CM_ "AUTOGENERATED FILE, DO NOT EDIT";

CM_ "hyundai_kia_mando_front_radar.dbc starts here";

VERSION ""

NS_ :

BS_:

BU_: XXX

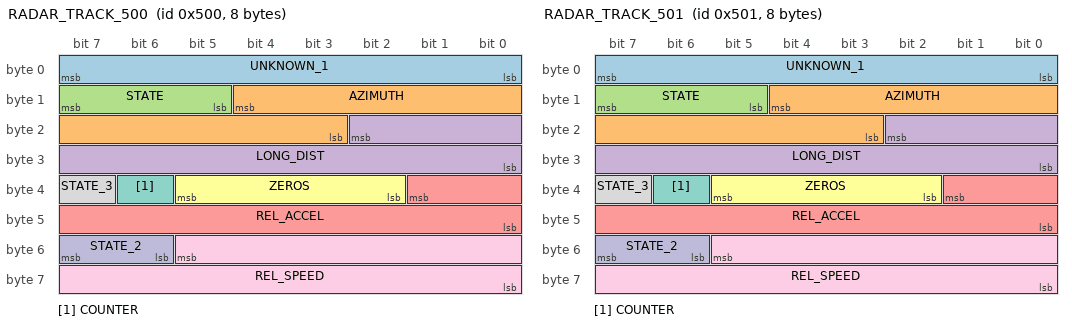
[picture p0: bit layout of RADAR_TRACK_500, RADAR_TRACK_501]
BO_ 1280 RADAR_TRACK_500: 8 RADAR
 SG_ UNKNOWN_1 : 7|8@0- (1,0) [-128|127] "" XXX
 SG_ AZIMUTH : 12|10@0- (0.2,0) [-102.4|102.2] "" XXX
 SG_ STATE : 15|3@0+ (1,0) [0|7] "" XXX
 SG_ LONG_DIST : 18|11@0+ (0.1,0) [0|204.7] "" XXX
 SG_ REL_ACCEL : 33|10@0- (0.02,0) [-10.24|10.22] "" XXX
 SG_ ZEROS : 37|4@0+ (1,0) [0|255] "" XXX
 SG_ COUNTER : 38|1@0+ (1,0) [0|1] "" XXX
 SG_ STATE_3 : 39|1@0+ (1,0) [0|1] "" XXX
 SG_ REL_SPEED : 53|14@0- (0.01,0) [-81.92|81.92] "" XXX
 SG_ STATE_2 : 55|2@0+ (1,0) [0|3] "" XXX

BO_ 1281 RADAR_TRACK_501: 8 RADAR
 SG_ UNKNOWN_1 : 7|8@0- (1,0) [-128|127] "" XXX
 SG_ AZIMUTH : 12|10@0- (0.2,0) [-102.4|102.2] "" XXX
 SG_ STATE : 15|3@0+ (1,0) [0|7] "" XXX
 SG_ LONG_DIST : 18|11@0+ (0.1,0) [0|204.7] "" XXX
 SG_ REL_ACCEL : 33|10@0- (0.02,0) [-10.24|10.22] "" XXX
 SG_ ZEROS : 37|4@0+ (1,0) [0|255] "" XXX
 SG_ COUNTER : 38|1@0+ (1,0) [0|1] "" XXX
 SG_ STATE_3 : 39|1@0+ (1,0) [0|1] "" XXX
 SG_ REL_SPEED : 53|14@0- (0.01,0) [-81.92|81.92] "" XXX
 SG_ STATE_2 : 55|2@0+ (1,0) [0|3] "" XXX

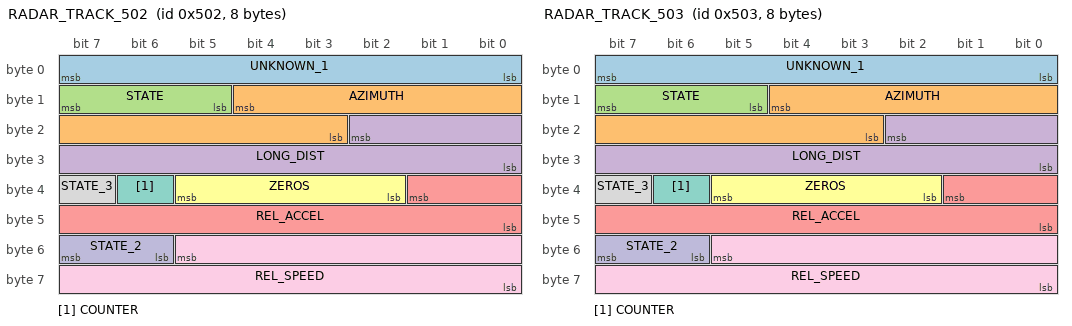
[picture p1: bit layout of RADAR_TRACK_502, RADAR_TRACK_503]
BO_ 1282 RADAR_TRACK_502: 8 RADAR
 SG_ UNKNOWN_1 : 7|8@0- (1,0) [-128|127] "" XXX
 SG_ AZIMUTH : 12|10@0- (0.2,0) [-102.4|102.2] "" XXX
 SG_ STATE : 15|3@0+ (1,0) [0|7] "" XXX
 SG_ LONG_DIST : 18|11@0+ (0.1,0) [0|204.7] "" XXX
 SG_ REL_ACCEL : 33|10@0- (0.02,0) [-10.24|10.22] "" XXX
 SG_ ZEROS : 37|4@0+ (1,0) [0|255] "" XXX
 SG_ COUNTER : 38|1@0+ (1,0) [0|1] "" XXX
 SG_ STATE_3 : 39|1@0+ (1,0) [0|1] "" XXX
 SG_ REL_SPEED : 53|14@0- (0.01,0) [-81.92|81.92] "" XXX
 SG_ STATE_2 : 55|2@0+ (1,0) [0|3] "" XXX

BO_ 1283 RADAR_TRACK_503: 8 RADAR
 SG_ UNKNOWN_1 : 7|8@0- (1,0) [-128|127] "" XXX
 SG_ AZIMUTH : 12|10@0- (0.2,0) [-102.4|102.2] "" XXX
 SG_ STATE : 15|3@0+ (1,0) [0|7] "" XXX
 SG_ LONG_DIST : 18|11@0+ (0.1,0) [0|204.7] "" XXX
 SG_ REL_ACCEL : 33|10@0- (0.02,0) [-10.24|10.22] "" XXX
 SG_ ZEROS : 37|4@0+ (1,0) [0|255] "" XXX
 SG_ COUNTER : 38|1@0+ (1,0) [0|1] "" XXX
 SG_ STATE_3 : 39|1@0+ (1,0) [0|1] "" XXX
 SG_ REL_SPEED : 53|14@0- (0.01,0) [-81.92|81.92] "" XXX
 SG_ STATE_2 : 55|2@0+ (1,0) [0|3] "" XXX

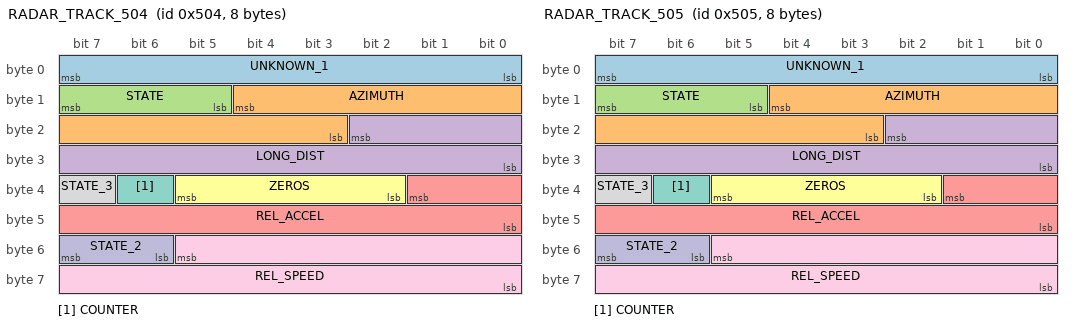
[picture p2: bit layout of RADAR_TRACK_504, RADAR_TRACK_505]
BO_ 1284 RADAR_TRACK_504: 8 RADAR
 SG_ UNKNOWN_1 : 7|8@0- (1,0) [-128|127] "" XXX
 SG_ AZIMUTH : 12|10@0- (0.2,0) [-102.4|102.2] "" XXX
 SG_ STATE : 15|3@0+ (1,0) [0|7] "" XXX
 SG_ LONG_DIST : 18|11@0+ (0.1,0) [0|204.7] "" XXX
 SG_ REL_ACCEL : 33|10@0- (0.02,0) [-10.24|10.22] "" XXX
 SG_ ZEROS : 37|4@0+ (1,0) [0|255] "" XXX
 SG_ COUNTER : 38|1@0+ (1,0) [0|1] "" XXX
 SG_ STATE_3 : 39|1@0+ (1,0) [0|1] "" XXX
 SG_ REL_SPEED : 53|14@0- (0.01,0) [-81.92|81.92] "" XXX
 SG_ STATE_2 : 55|2@0+ (1,0) [0|3] "" XXX

BO_ 1285 RADAR_TRACK_505: 8 RADAR
 SG_ UNKNOWN_1 : 7|8@0- (1,0) [-128|127] "" XXX
 SG_ AZIMUTH : 12|10@0- (0.2,0) [-102.4|102.2] "" XXX
 SG_ STATE : 15|3@0+ (1,0) [0|7] "" XXX
 SG_ LONG_DIST : 18|11@0+ (0.1,0) [0|204.7] "" XXX
 SG_ REL_ACCEL : 33|10@0- (0.02,0) [-10.24|10.22] "" XXX
 SG_ ZEROS : 37|4@0+ (1,0) [0|255] "" XXX
 SG_ COUNTER : 38|1@0+ (1,0) [0|1] "" XXX
 SG_ STATE_3 : 39|1@0+ (1,0) [0|1] "" XXX
 SG_ REL_SPEED : 53|14@0- (0.01,0) [-81.92|81.92] "" XXX
 SG_ STATE_2 : 55|2@0+ (1,0) [0|3] "" XXX

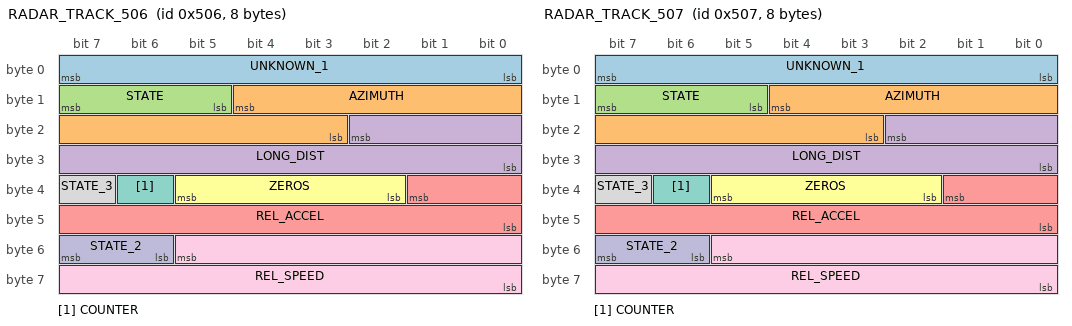
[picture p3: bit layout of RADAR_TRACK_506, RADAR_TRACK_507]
BO_ 1286 RADAR_TRACK_506: 8 RADAR
 SG_ UNKNOWN_1 : 7|8@0- (1,0) [-128|127] "" XXX
 SG_ AZIMUTH : 12|10@0- (0.2,0) [-102.4|102.2] "" XXX
 SG_ STATE : 15|3@0+ (1,0) [0|7] "" XXX
 SG_ LONG_DIST : 18|11@0+ (0.1,0) [0|204.7] "" XXX
 SG_ REL_ACCEL : 33|10@0- (0.02,0) [-10.24|10.22] "" XXX
 SG_ ZEROS : 37|4@0+ (1,0) [0|255] "" XXX
 SG_ COUNTER : 38|1@0+ (1,0) [0|1] "" XXX
 SG_ STATE_3 : 39|1@0+ (1,0) [0|1] "" XXX
 SG_ REL_SPEED : 53|14@0- (0.01,0) [-81.92|81.92] "" XXX
 SG_ STATE_2 : 55|2@0+ (1,0) [0|3] "" XXX

BO_ 1287 RADAR_TRACK_507: 8 RADAR
 SG_ UNKNOWN_1 : 7|8@0- (1,0) [-128|127] "" XXX
 SG_ AZIMUTH : 12|10@0- (0.2,0) [-102.4|102.2] "" XXX
 SG_ STATE : 15|3@0+ (1,0) [0|7] "" XXX
 SG_ LONG_DIST : 18|11@0+ (0.1,0) [0|204.7] "" XXX
 SG_ REL_ACCEL : 33|10@0- (0.02,0) [-10.24|10.22] "" XXX
 SG_ ZEROS : 37|4@0+ (1,0) [0|255] "" XXX
 SG_ COUNTER : 38|1@0+ (1,0) [0|1] "" XXX
 SG_ STATE_3 : 39|1@0+ (1,0) [0|1] "" XXX
 SG_ REL_SPEED : 53|14@0- (0.01,0) [-81.92|81.92] "" XXX
 SG_ STATE_2 : 55|2@0+ (1,0) [0|3] "" XXX

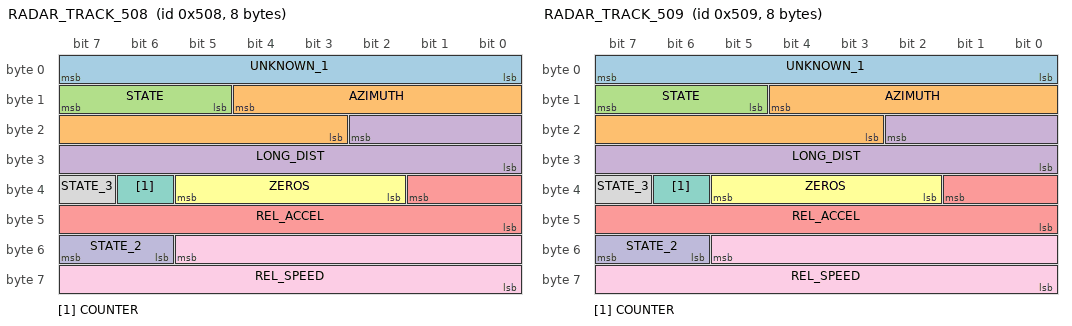
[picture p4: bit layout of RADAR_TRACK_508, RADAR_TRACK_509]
BO_ 1288 RADAR_TRACK_508: 8 RADAR
 SG_ UNKNOWN_1 : 7|8@0- (1,0) [-128|127] "" XXX
 SG_ AZIMUTH : 12|10@0- (0.2,0) [-102.4|102.2] "" XXX
 SG_ STATE : 15|3@0+ (1,0) [0|7] "" XXX
 SG_ LONG_DIST : 18|11@0+ (0.1,0) [0|204.7] "" XXX
 SG_ REL_ACCEL : 33|10@0- (0.02,0) [-10.24|10.22] "" XXX
 SG_ ZEROS : 37|4@0+ (1,0) [0|255] "" XXX
 SG_ COUNTER : 38|1@0+ (1,0) [0|1] "" XXX
 SG_ STATE_3 : 39|1@0+ (1,0) [0|1] "" XXX
 SG_ REL_SPEED : 53|14@0- (0.01,0) [-81.92|81.92] "" XXX
 SG_ STATE_2 : 55|2@0+ (1,0) [0|3] "" XXX

BO_ 1289 RADAR_TRACK_509: 8 RADAR
 SG_ UNKNOWN_1 : 7|8@0- (1,0) [-128|127] "" XXX
 SG_ AZIMUTH : 12|10@0- (0.2,0) [-102.4|102.2] "" XXX
 SG_ STATE : 15|3@0+ (1,0) [0|7] "" XXX
 SG_ LONG_DIST : 18|11@0+ (0.1,0) [0|204.7] "" XXX
 SG_ REL_ACCEL : 33|10@0- (0.02,0) [-10.24|10.22] "" XXX
 SG_ ZEROS : 37|4@0+ (1,0) [0|255] "" XXX
 SG_ COUNTER : 38|1@0+ (1,0) [0|1] "" XXX
 SG_ STATE_3 : 39|1@0+ (1,0) [0|1] "" XXX
 SG_ REL_SPEED : 53|14@0- (0.01,0) [-81.92|81.92] "" XXX
 SG_ STATE_2 : 55|2@0+ (1,0) [0|3] "" XXX

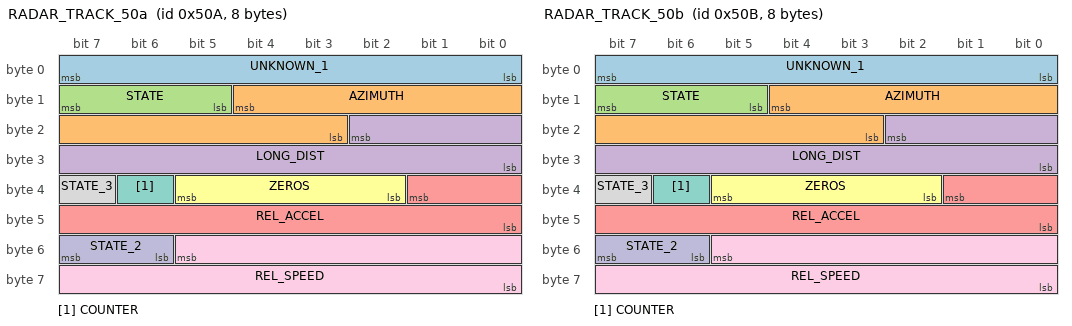
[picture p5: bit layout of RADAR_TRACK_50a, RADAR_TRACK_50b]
BO_ 1290 RADAR_TRACK_50a: 8 RADAR
 SG_ UNKNOWN_1 : 7|8@0- (1,0) [-128|127] "" XXX
 SG_ AZIMUTH : 12|10@0- (0.2,0) [-102.4|102.2] "" XXX
 SG_ STATE : 15|3@0+ (1,0) [0|7] "" XXX
 SG_ LONG_DIST : 18|11@0+ (0.1,0) [0|204.7] "" XXX
 SG_ REL_ACCEL : 33|10@0- (0.02,0) [-10.24|10.22] "" XXX
 SG_ ZEROS : 37|4@0+ (1,0) [0|255] "" XXX
 SG_ COUNTER : 38|1@0+ (1,0) [0|1] "" XXX
 SG_ STATE_3 : 39|1@0+ (1,0) [0|1] "" XXX
 SG_ REL_SPEED : 53|14@0- (0.01,0) [-81.92|81.92] "" XXX
 SG_ STATE_2 : 55|2@0+ (1,0) [0|3] "" XXX

BO_ 1291 RADAR_TRACK_50b: 8 RADAR
 SG_ UNKNOWN_1 : 7|8@0- (1,0) [-128|127] "" XXX
 SG_ AZIMUTH : 12|10@0- (0.2,0) [-102.4|102.2] "" XXX
 SG_ STATE : 15|3@0+ (1,0) [0|7] "" XXX
 SG_ LONG_DIST : 18|11@0+ (0.1,0) [0|204.7] "" XXX
 SG_ REL_ACCEL : 33|10@0- (0.02,0) [-10.24|10.22] "" XXX
 SG_ ZEROS : 37|4@0+ (1,0) [0|255] "" XXX
 SG_ COUNTER : 38|1@0+ (1,0) [0|1] "" XXX
 SG_ STATE_3 : 39|1@0+ (1,0) [0|1] "" XXX
 SG_ REL_SPEED : 53|14@0- (0.01,0) [-81.92|81.92] "" XXX
 SG_ STATE_2 : 55|2@0+ (1,0) [0|3] "" XXX

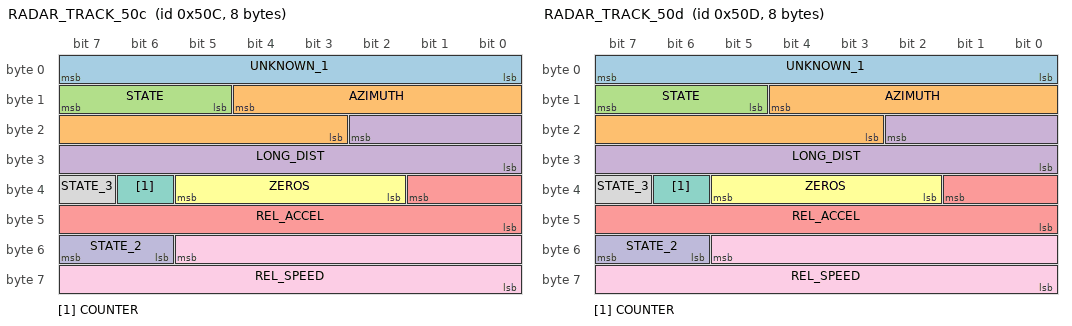
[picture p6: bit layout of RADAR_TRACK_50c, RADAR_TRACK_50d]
BO_ 1292 RADAR_TRACK_50c: 8 RADAR
 SG_ UNKNOWN_1 : 7|8@0- (1,0) [-128|127] "" XXX
 SG_ AZIMUTH : 12|10@0- (0.2,0) [-102.4|102.2] "" XXX
 SG_ STATE : 15|3@0+ (1,0) [0|7] "" XXX
 SG_ LONG_DIST : 18|11@0+ (0.1,0) [0|204.7] "" XXX
 SG_ REL_ACCEL : 33|10@0- (0.02,0) [-10.24|10.22] "" XXX
 SG_ ZEROS : 37|4@0+ (1,0) [0|255] "" XXX
 SG_ COUNTER : 38|1@0+ (1,0) [0|1] "" XXX
 SG_ STATE_3 : 39|1@0+ (1,0) [0|1] "" XXX
 SG_ REL_SPEED : 53|14@0- (0.01,0) [-81.92|81.92] "" XXX
 SG_ STATE_2 : 55|2@0+ (1,0) [0|3] "" XXX

BO_ 1293 RADAR_TRACK_50d: 8 RADAR
 SG_ UNKNOWN_1 : 7|8@0- (1,0) [-128|127] "" XXX
 SG_ AZIMUTH : 12|10@0- (0.2,0) [-102.4|102.2] "" XXX
 SG_ STATE : 15|3@0+ (1,0) [0|7] "" XXX
 SG_ LONG_DIST : 18|11@0+ (0.1,0) [0|204.7] "" XXX
 SG_ REL_ACCEL : 33|10@0- (0.02,0) [-10.24|10.22] "" XXX
 SG_ ZEROS : 37|4@0+ (1,0) [0|255] "" XXX
 SG_ COUNTER : 38|1@0+ (1,0) [0|1] "" XXX
 SG_ STATE_3 : 39|1@0+ (1,0) [0|1] "" XXX
 SG_ REL_SPEED : 53|14@0- (0.01,0) [-81.92|81.92] "" XXX
 SG_ STATE_2 : 55|2@0+ (1,0) [0|3] "" XXX

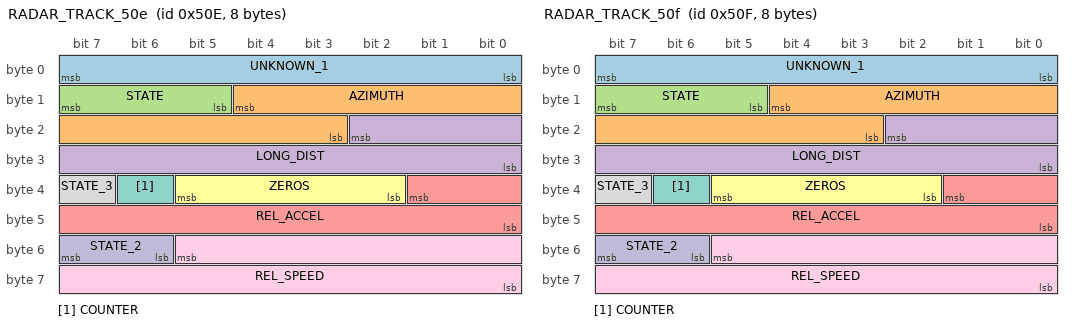
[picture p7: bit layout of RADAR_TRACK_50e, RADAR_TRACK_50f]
BO_ 1294 RADAR_TRACK_50e: 8 RADAR
 SG_ UNKNOWN_1 : 7|8@0- (1,0) [-128|127] "" XXX
 SG_ AZIMUTH : 12|10@0- (0.2,0) [-102.4|102.2] "" XXX
 SG_ STATE : 15|3@0+ (1,0) [0|7] "" XXX
 SG_ LONG_DIST : 18|11@0+ (0.1,0) [0|204.7] "" XXX
 SG_ REL_ACCEL : 33|10@0- (0.02,0) [-10.24|10.22] "" XXX
 SG_ ZEROS : 37|4@0+ (1,0) [0|255] "" XXX
 SG_ COUNTER : 38|1@0+ (1,0) [0|1] "" XXX
 SG_ STATE_3 : 39|1@0+ (1,0) [0|1] "" XXX
 SG_ REL_SPEED : 53|14@0- (0.01,0) [-81.92|81.92] "" XXX
 SG_ STATE_2 : 55|2@0+ (1,0) [0|3] "" XXX

BO_ 1295 RADAR_TRACK_50f: 8 RADAR
 SG_ UNKNOWN_1 : 7|8@0- (1,0) [-128|127] "" XXX
 SG_ AZIMUTH : 12|10@0- (0.2,0) [-102.4|102.2] "" XXX
 SG_ STATE : 15|3@0+ (1,0) [0|7] "" XXX
 SG_ LONG_DIST : 18|11@0+ (0.1,0) [0|204.7] "" XXX
 SG_ REL_ACCEL : 33|10@0- (0.02,0) [-10.24|10.22] "" XXX
 SG_ ZEROS : 37|4@0+ (1,0) [0|255] "" XXX
 SG_ COUNTER : 38|1@0+ (1,0) [0|1] "" XXX
 SG_ STATE_3 : 39|1@0+ (1,0) [0|1] "" XXX
 SG_ REL_SPEED : 53|14@0- (0.01,0) [-81.92|81.92] "" XXX
 SG_ STATE_2 : 55|2@0+ (1,0) [0|3] "" XXX

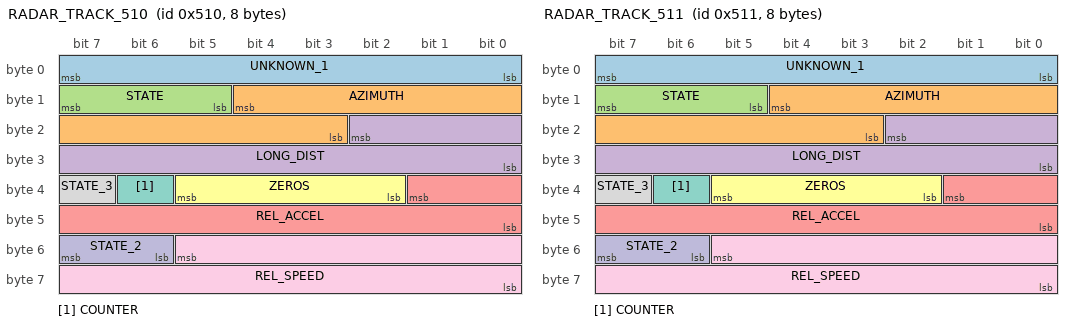
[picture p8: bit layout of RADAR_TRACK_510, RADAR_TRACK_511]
BO_ 1296 RADAR_TRACK_510: 8 RADAR
 SG_ UNKNOWN_1 : 7|8@0- (1,0) [-128|127] "" XXX
 SG_ AZIMUTH : 12|10@0- (0.2,0) [-102.4|102.2] "" XXX
 SG_ STATE : 15|3@0+ (1,0) [0|7] "" XXX
 SG_ LONG_DIST : 18|11@0+ (0.1,0) [0|204.7] "" XXX
 SG_ REL_ACCEL : 33|10@0- (0.02,0) [-10.24|10.22] "" XXX
 SG_ ZEROS : 37|4@0+ (1,0) [0|255] "" XXX
 SG_ COUNTER : 38|1@0+ (1,0) [0|1] "" XXX
 SG_ STATE_3 : 39|1@0+ (1,0) [0|1] "" XXX
 SG_ REL_SPEED : 53|14@0- (0.01,0) [-81.92|81.92] "" XXX
 SG_ STATE_2 : 55|2@0+ (1,0) [0|3] "" XXX

BO_ 1297 RADAR_TRACK_511: 8 RADAR
 SG_ UNKNOWN_1 : 7|8@0- (1,0) [-128|127] "" XXX
 SG_ AZIMUTH : 12|10@0- (0.2,0) [-102.4|102.2] "" XXX
 SG_ STATE : 15|3@0+ (1,0) [0|7] "" XXX
 SG_ LONG_DIST : 18|11@0+ (0.1,0) [0|204.7] "" XXX
 SG_ REL_ACCEL : 33|10@0- (0.02,0) [-10.24|10.22] "" XXX
 SG_ ZEROS : 37|4@0+ (1,0) [0|255] "" XXX
 SG_ COUNTER : 38|1@0+ (1,0) [0|1] "" XXX
 SG_ STATE_3 : 39|1@0+ (1,0) [0|1] "" XXX
 SG_ REL_SPEED : 53|14@0- (0.01,0) [-81.92|81.92] "" XXX
 SG_ STATE_2 : 55|2@0+ (1,0) [0|3] "" XXX

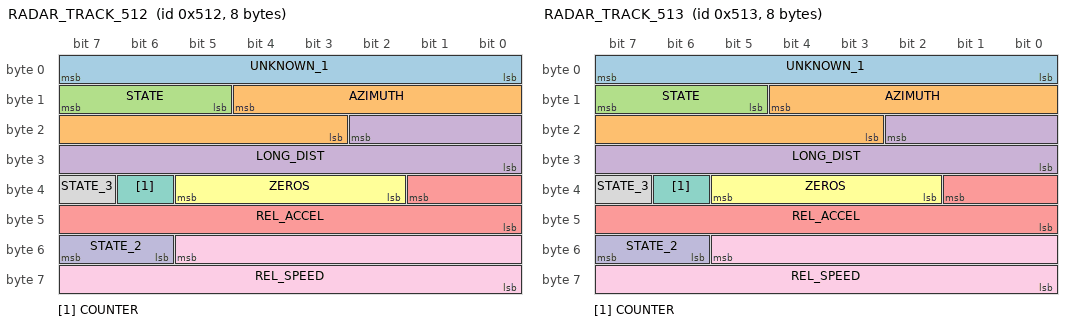
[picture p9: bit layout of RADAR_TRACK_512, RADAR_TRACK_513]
BO_ 1298 RADAR_TRACK_512: 8 RADAR
 SG_ UNKNOWN_1 : 7|8@0- (1,0) [-128|127] "" XXX
 SG_ AZIMUTH : 12|10@0- (0.2,0) [-102.4|102.2] "" XXX
 SG_ STATE : 15|3@0+ (1,0) [0|7] "" XXX
 SG_ LONG_DIST : 18|11@0+ (0.1,0) [0|204.7] "" XXX
 SG_ REL_ACCEL : 33|10@0- (0.02,0) [-10.24|10.22] "" XXX
 SG_ ZEROS : 37|4@0+ (1,0) [0|255] "" XXX
 SG_ COUNTER : 38|1@0+ (1,0) [0|1] "" XXX
 SG_ STATE_3 : 39|1@0+ (1,0) [0|1] "" XXX
 SG_ REL_SPEED : 53|14@0- (0.01,0) [-81.92|81.92] "" XXX
 SG_ STATE_2 : 55|2@0+ (1,0) [0|3] "" XXX

BO_ 1299 RADAR_TRACK_513: 8 RADAR
 SG_ UNKNOWN_1 : 7|8@0- (1,0) [-128|127] "" XXX
 SG_ AZIMUTH : 12|10@0- (0.2,0) [-102.4|102.2] "" XXX
 SG_ STATE : 15|3@0+ (1,0) [0|7] "" XXX
 SG_ LONG_DIST : 18|11@0+ (0.1,0) [0|204.7] "" XXX
 SG_ REL_ACCEL : 33|10@0- (0.02,0) [-10.24|10.22] "" XXX
 SG_ ZEROS : 37|4@0+ (1,0) [0|255] "" XXX
 SG_ COUNTER : 38|1@0+ (1,0) [0|1] "" XXX
 SG_ STATE_3 : 39|1@0+ (1,0) [0|1] "" XXX
 SG_ REL_SPEED : 53|14@0- (0.01,0) [-81.92|81.92] "" XXX
 SG_ STATE_2 : 55|2@0+ (1,0) [0|3] "" XXX

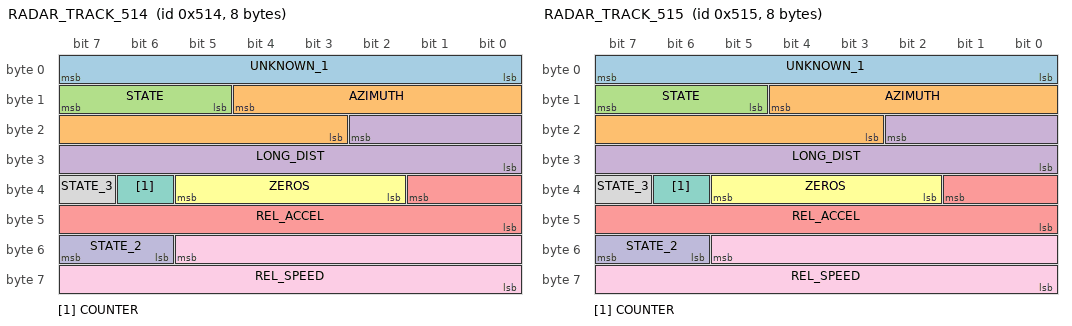
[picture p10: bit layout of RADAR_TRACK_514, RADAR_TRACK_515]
BO_ 1300 RADAR_TRACK_514: 8 RADAR
 SG_ UNKNOWN_1 : 7|8@0- (1,0) [-128|127] "" XXX
 SG_ AZIMUTH : 12|10@0- (0.2,0) [-102.4|102.2] "" XXX
 SG_ STATE : 15|3@0+ (1,0) [0|7] "" XXX
 SG_ LONG_DIST : 18|11@0+ (0.1,0) [0|204.7] "" XXX
 SG_ REL_ACCEL : 33|10@0- (0.02,0) [-10.24|10.22] "" XXX
 SG_ ZEROS : 37|4@0+ (1,0) [0|255] "" XXX
 SG_ COUNTER : 38|1@0+ (1,0) [0|1] "" XXX
 SG_ STATE_3 : 39|1@0+ (1,0) [0|1] "" XXX
 SG_ REL_SPEED : 53|14@0- (0.01,0) [-81.92|81.92] "" XXX
 SG_ STATE_2 : 55|2@0+ (1,0) [0|3] "" XXX

BO_ 1301 RADAR_TRACK_515: 8 RADAR
 SG_ UNKNOWN_1 : 7|8@0- (1,0) [-128|127] "" XXX
 SG_ AZIMUTH : 12|10@0- (0.2,0) [-102.4|102.2] "" XXX
 SG_ STATE : 15|3@0+ (1,0) [0|7] "" XXX
 SG_ LONG_DIST : 18|11@0+ (0.1,0) [0|204.7] "" XXX
 SG_ REL_ACCEL : 33|10@0- (0.02,0) [-10.24|10.22] "" XXX
 SG_ ZEROS : 37|4@0+ (1,0) [0|255] "" XXX
 SG_ COUNTER : 38|1@0+ (1,0) [0|1] "" XXX
 SG_ STATE_3 : 39|1@0+ (1,0) [0|1] "" XXX
 SG_ REL_SPEED : 53|14@0- (0.01,0) [-81.92|81.92] "" XXX
 SG_ STATE_2 : 55|2@0+ (1,0) [0|3] "" XXX

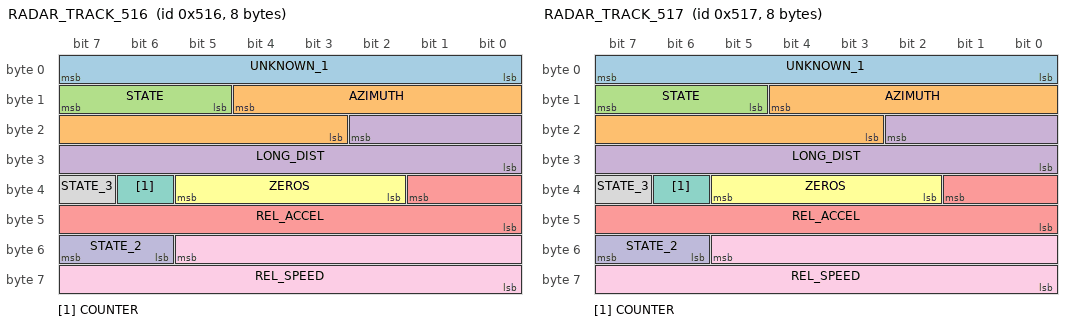
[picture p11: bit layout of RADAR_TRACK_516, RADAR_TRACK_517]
BO_ 1302 RADAR_TRACK_516: 8 RADAR
 SG_ UNKNOWN_1 : 7|8@0- (1,0) [-128|127] "" XXX
 SG_ AZIMUTH : 12|10@0- (0.2,0) [-102.4|102.2] "" XXX
 SG_ STATE : 15|3@0+ (1,0) [0|7] "" XXX
 SG_ LONG_DIST : 18|11@0+ (0.1,0) [0|204.7] "" XXX
 SG_ REL_ACCEL : 33|10@0- (0.02,0) [-10.24|10.22] "" XXX
 SG_ ZEROS : 37|4@0+ (1,0) [0|255] "" XXX
 SG_ COUNTER : 38|1@0+ (1,0) [0|1] "" XXX
 SG_ STATE_3 : 39|1@0+ (1,0) [0|1] "" XXX
 SG_ REL_SPEED : 53|14@0- (0.01,0) [-81.92|81.92] "" XXX
 SG_ STATE_2 : 55|2@0+ (1,0) [0|3] "" XXX

BO_ 1303 RADAR_TRACK_517: 8 RADAR
 SG_ UNKNOWN_1 : 7|8@0- (1,0) [-128|127] "" XXX
 SG_ AZIMUTH : 12|10@0- (0.2,0) [-102.4|102.2] "" XXX
 SG_ STATE : 15|3@0+ (1,0) [0|7] "" XXX
 SG_ LONG_DIST : 18|11@0+ (0.1,0) [0|204.7] "" XXX
 SG_ REL_ACCEL : 33|10@0- (0.02,0) [-10.24|10.22] "" XXX
 SG_ ZEROS : 37|4@0+ (1,0) [0|255] "" XXX
 SG_ COUNTER : 38|1@0+ (1,0) [0|1] "" XXX
 SG_ STATE_3 : 39|1@0+ (1,0) [0|1] "" XXX
 SG_ REL_SPEED : 53|14@0- (0.01,0) [-81.92|81.92] "" XXX
 SG_ STATE_2 : 55|2@0+ (1,0) [0|3] "" XXX

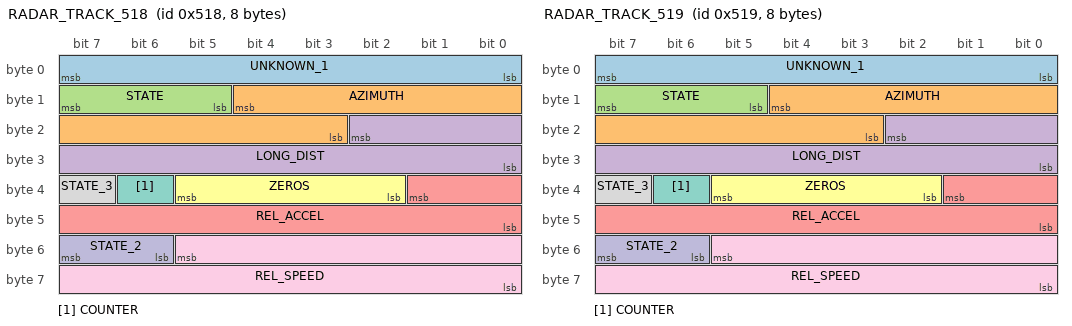
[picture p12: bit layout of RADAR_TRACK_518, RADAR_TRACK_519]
BO_ 1304 RADAR_TRACK_518: 8 RADAR
 SG_ UNKNOWN_1 : 7|8@0- (1,0) [-128|127] "" XXX
 SG_ AZIMUTH : 12|10@0- (0.2,0) [-102.4|102.2] "" XXX
 SG_ STATE : 15|3@0+ (1,0) [0|7] "" XXX
 SG_ LONG_DIST : 18|11@0+ (0.1,0) [0|204.7] "" XXX
 SG_ REL_ACCEL : 33|10@0- (0.02,0) [-10.24|10.22] "" XXX
 SG_ ZEROS : 37|4@0+ (1,0) [0|255] "" XXX
 SG_ COUNTER : 38|1@0+ (1,0) [0|1] "" XXX
 SG_ STATE_3 : 39|1@0+ (1,0) [0|1] "" XXX
 SG_ REL_SPEED : 53|14@0- (0.01,0) [-81.92|81.92] "" XXX
 SG_ STATE_2 : 55|2@0+ (1,0) [0|3] "" XXX

BO_ 1305 RADAR_TRACK_519: 8 RADAR
 SG_ UNKNOWN_1 : 7|8@0- (1,0) [-128|127] "" XXX
 SG_ AZIMUTH : 12|10@0- (0.2,0) [-102.4|102.2] "" XXX
 SG_ STATE : 15|3@0+ (1,0) [0|7] "" XXX
 SG_ LONG_DIST : 18|11@0+ (0.1,0) [0|204.7] "" XXX
 SG_ REL_ACCEL : 33|10@0- (0.02,0) [-10.24|10.22] "" XXX
 SG_ ZEROS : 37|4@0+ (1,0) [0|255] "" XXX
 SG_ COUNTER : 38|1@0+ (1,0) [0|1] "" XXX
 SG_ STATE_3 : 39|1@0+ (1,0) [0|1] "" XXX
 SG_ REL_SPEED : 53|14@0- (0.01,0) [-81.92|81.92] "" XXX
 SG_ STATE_2 : 55|2@0+ (1,0) [0|3] "" XXX

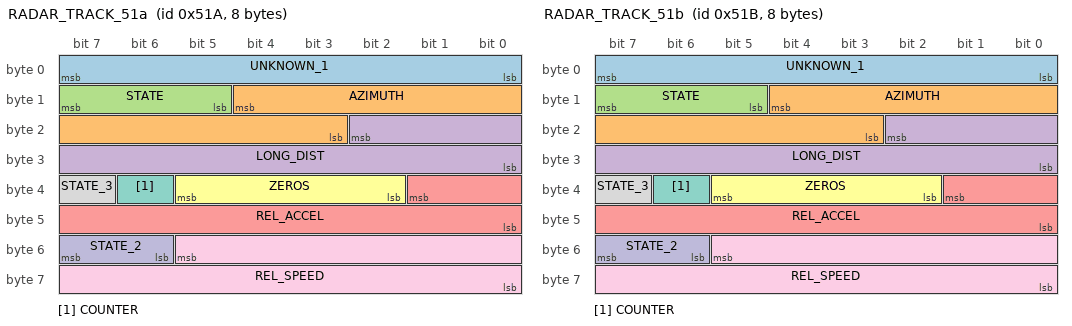
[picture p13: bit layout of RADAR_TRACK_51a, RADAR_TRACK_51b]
BO_ 1306 RADAR_TRACK_51a: 8 RADAR
 SG_ UNKNOWN_1 : 7|8@0- (1,0) [-128|127] "" XXX
 SG_ AZIMUTH : 12|10@0- (0.2,0) [-102.4|102.2] "" XXX
 SG_ STATE : 15|3@0+ (1,0) [0|7] "" XXX
 SG_ LONG_DIST : 18|11@0+ (0.1,0) [0|204.7] "" XXX
 SG_ REL_ACCEL : 33|10@0- (0.02,0) [-10.24|10.22] "" XXX
 SG_ ZEROS : 37|4@0+ (1,0) [0|255] "" XXX
 SG_ COUNTER : 38|1@0+ (1,0) [0|1] "" XXX
 SG_ STATE_3 : 39|1@0+ (1,0) [0|1] "" XXX
 SG_ REL_SPEED : 53|14@0- (0.01,0) [-81.92|81.92] "" XXX
 SG_ STATE_2 : 55|2@0+ (1,0) [0|3] "" XXX

BO_ 1307 RADAR_TRACK_51b: 8 RADAR
 SG_ UNKNOWN_1 : 7|8@0- (1,0) [-128|127] "" XXX
 SG_ AZIMUTH : 12|10@0- (0.2,0) [-102.4|102.2] "" XXX
 SG_ STATE : 15|3@0+ (1,0) [0|7] "" XXX
 SG_ LONG_DIST : 18|11@0+ (0.1,0) [0|204.7] "" XXX
 SG_ REL_ACCEL : 33|10@0- (0.02,0) [-10.24|10.22] "" XXX
 SG_ ZEROS : 37|4@0+ (1,0) [0|255] "" XXX
 SG_ COUNTER : 38|1@0+ (1,0) [0|1] "" XXX
 SG_ STATE_3 : 39|1@0+ (1,0) [0|1] "" XXX
 SG_ REL_SPEED : 53|14@0- (0.01,0) [-81.92|81.92] "" XXX
 SG_ STATE_2 : 55|2@0+ (1,0) [0|3] "" XXX

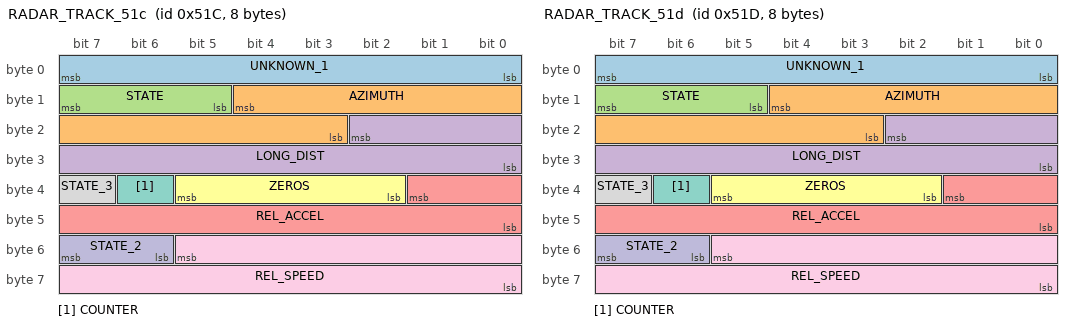
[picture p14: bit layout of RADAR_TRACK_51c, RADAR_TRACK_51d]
BO_ 1308 RADAR_TRACK_51c: 8 RADAR
 SG_ UNKNOWN_1 : 7|8@0- (1,0) [-128|127] "" XXX
 SG_ AZIMUTH : 12|10@0- (0.2,0) [-102.4|102.2] "" XXX
 SG_ STATE : 15|3@0+ (1,0) [0|7] "" XXX
 SG_ LONG_DIST : 18|11@0+ (0.1,0) [0|204.7] "" XXX
 SG_ REL_ACCEL : 33|10@0- (0.02,0) [-10.24|10.22] "" XXX
 SG_ ZEROS : 37|4@0+ (1,0) [0|255] "" XXX
 SG_ COUNTER : 38|1@0+ (1,0) [0|1] "" XXX
 SG_ STATE_3 : 39|1@0+ (1,0) [0|1] "" XXX
 SG_ REL_SPEED : 53|14@0- (0.01,0) [-81.92|81.92] "" XXX
 SG_ STATE_2 : 55|2@0+ (1,0) [0|3] "" XXX

BO_ 1309 RADAR_TRACK_51d: 8 RADAR
 SG_ UNKNOWN_1 : 7|8@0- (1,0) [-128|127] "" XXX
 SG_ AZIMUTH : 12|10@0- (0.2,0) [-102.4|102.2] "" XXX
 SG_ STATE : 15|3@0+ (1,0) [0|7] "" XXX
 SG_ LONG_DIST : 18|11@0+ (0.1,0) [0|204.7] "" XXX
 SG_ REL_ACCEL : 33|10@0- (0.02,0) [-10.24|10.22] "" XXX
 SG_ ZEROS : 37|4@0+ (1,0) [0|255] "" XXX
 SG_ COUNTER : 38|1@0+ (1,0) [0|1] "" XXX
 SG_ STATE_3 : 39|1@0+ (1,0) [0|1] "" XXX
 SG_ REL_SPEED : 53|14@0- (0.01,0) [-81.92|81.92] "" XXX
 SG_ STATE_2 : 55|2@0+ (1,0) [0|3] "" XXX

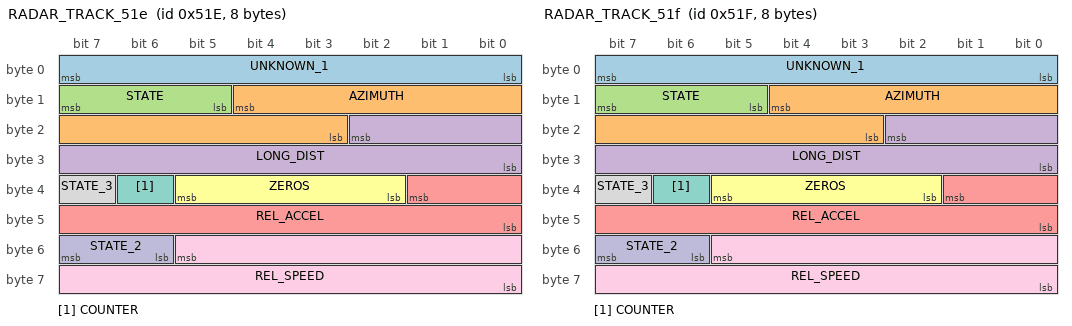
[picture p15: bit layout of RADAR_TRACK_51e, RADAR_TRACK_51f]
BO_ 1310 RADAR_TRACK_51e: 8 RADAR
 SG_ UNKNOWN_1 : 7|8@0- (1,0) [-128|127] "" XXX
 SG_ AZIMUTH : 12|10@0- (0.2,0) [-102.4|102.2] "" XXX
 SG_ STATE : 15|3@0+ (1,0) [0|7] "" XXX
 SG_ LONG_DIST : 18|11@0+ (0.1,0) [0|204.7] "" XXX
 SG_ REL_ACCEL : 33|10@0- (0.02,0) [-10.24|10.22] "" XXX
 SG_ ZEROS : 37|4@0+ (1,0) [0|255] "" XXX
 SG_ COUNTER : 38|1@0+ (1,0) [0|1] "" XXX
 SG_ STATE_3 : 39|1@0+ (1,0) [0|1] "" XXX
 SG_ REL_SPEED : 53|14@0- (0.01,0) [-81.92|81.92] "" XXX
 SG_ STATE_2 : 55|2@0+ (1,0) [0|3] "" XXX

BO_ 1311 RADAR_TRACK_51f: 8 RADAR
 SG_ UNKNOWN_1 : 7|8@0- (1,0) [-128|127] "" XXX
 SG_ AZIMUTH : 12|10@0- (0.2,0) [-102.4|102.2] "" XXX
 SG_ STATE : 15|3@0+ (1,0) [0|7] "" XXX
 SG_ LONG_DIST : 18|11@0+ (0.1,0) [0|204.7] "" XXX
 SG_ REL_ACCEL : 33|10@0- (0.02,0) [-10.24|10.22] "" XXX
 SG_ ZEROS : 37|4@0+ (1,0) [0|255] "" XXX
 SG_ COUNTER : 38|1@0+ (1,0) [0|1] "" XXX
 SG_ STATE_3 : 39|1@0+ (1,0) [0|1] "" XXX
 SG_ REL_SPEED : 53|14@0- (0.01,0) [-81.92|81.92] "" XXX
 SG_ STATE_2 : 55|2@0+ (1,0) [0|3] "" XXX

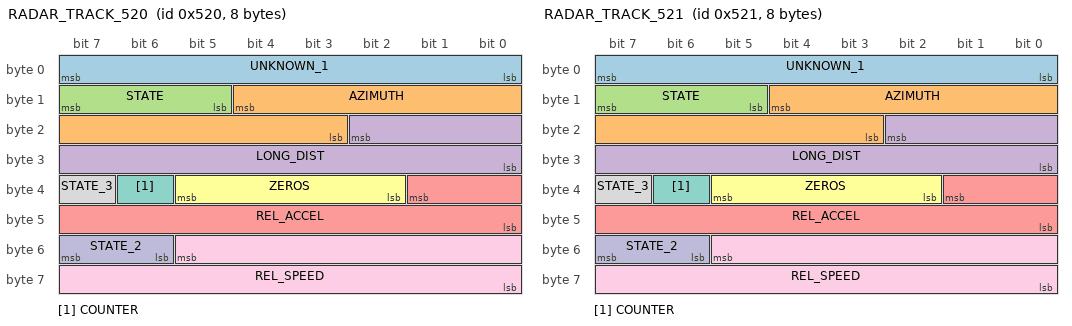
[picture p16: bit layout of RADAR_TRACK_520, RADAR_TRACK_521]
BO_ 1312 RADAR_TRACK_520: 8 RADAR
 SG_ UNKNOWN_1 : 7|8@0- (1,0) [-128|127] "" XXX
 SG_ AZIMUTH : 12|10@0- (0.2,0) [-102.4|102.2] "" XXX
 SG_ STATE : 15|3@0+ (1,0) [0|7] "" XXX
 SG_ LONG_DIST : 18|11@0+ (0.1,0) [0|204.7] "" XXX
 SG_ REL_ACCEL : 33|10@0- (0.02,0) [-10.24|10.22] "" XXX
 SG_ ZEROS : 37|4@0+ (1,0) [0|255] "" XXX
 SG_ COUNTER : 38|1@0+ (1,0) [0|1] "" XXX
 SG_ STATE_3 : 39|1@0+ (1,0) [0|1] "" XXX
 SG_ REL_SPEED : 53|14@0- (0.01,0) [-81.92|81.92] "" XXX
 SG_ STATE_2 : 55|2@0+ (1,0) [0|3] "" XXX

BO_ 1313 RADAR_TRACK_521: 8 RADAR
 SG_ UNKNOWN_1 : 7|8@0- (1,0) [-128|127] "" XXX
 SG_ AZIMUTH : 12|10@0- (0.2,0) [-102.4|102.2] "" XXX
 SG_ STATE : 15|3@0+ (1,0) [0|7] "" XXX
 SG_ LONG_DIST : 18|11@0+ (0.1,0) [0|204.7] "" XXX
 SG_ REL_ACCEL : 33|10@0- (0.02,0) [-10.24|10.22] "" XXX
 SG_ ZEROS : 37|4@0+ (1,0) [0|255] "" XXX
 SG_ COUNTER : 38|1@0+ (1,0) [0|1] "" XXX
 SG_ STATE_3 : 39|1@0+ (1,0) [0|1] "" XXX
 SG_ REL_SPEED : 53|14@0- (0.01,0) [-81.92|81.92] "" XXX
 SG_ STATE_2 : 55|2@0+ (1,0) [0|3] "" XXX

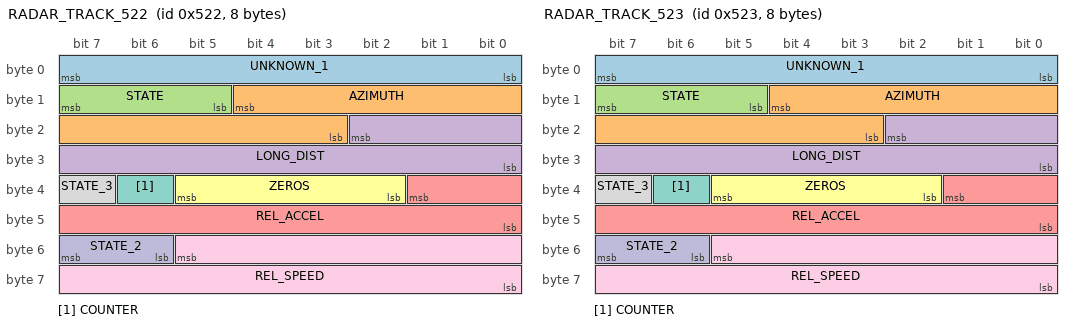
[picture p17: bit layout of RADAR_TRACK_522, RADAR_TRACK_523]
BO_ 1314 RADAR_TRACK_522: 8 RADAR
 SG_ UNKNOWN_1 : 7|8@0- (1,0) [-128|127] "" XXX
 SG_ AZIMUTH : 12|10@0- (0.2,0) [-102.4|102.2] "" XXX
 SG_ STATE : 15|3@0+ (1,0) [0|7] "" XXX
 SG_ LONG_DIST : 18|11@0+ (0.1,0) [0|204.7] "" XXX
 SG_ REL_ACCEL : 33|10@0- (0.02,0) [-10.24|10.22] "" XXX
 SG_ ZEROS : 37|4@0+ (1,0) [0|255] "" XXX
 SG_ COUNTER : 38|1@0+ (1,0) [0|1] "" XXX
 SG_ STATE_3 : 39|1@0+ (1,0) [0|1] "" XXX
 SG_ REL_SPEED : 53|14@0- (0.01,0) [-81.92|81.92] "" XXX
 SG_ STATE_2 : 55|2@0+ (1,0) [0|3] "" XXX

BO_ 1315 RADAR_TRACK_523: 8 RADAR
 SG_ UNKNOWN_1 : 7|8@0- (1,0) [-128|127] "" XXX
 SG_ AZIMUTH : 12|10@0- (0.2,0) [-102.4|102.2] "" XXX
 SG_ STATE : 15|3@0+ (1,0) [0|7] "" XXX
 SG_ LONG_DIST : 18|11@0+ (0.1,0) [0|204.7] "" XXX
 SG_ REL_ACCEL : 33|10@0- (0.02,0) [-10.24|10.22] "" XXX
 SG_ ZEROS : 37|4@0+ (1,0) [0|255] "" XXX
 SG_ COUNTER : 38|1@0+ (1,0) [0|1] "" XXX
 SG_ STATE_3 : 39|1@0+ (1,0) [0|1] "" XXX
 SG_ REL_SPEED : 53|14@0- (0.01,0) [-81.92|81.92] "" XXX
 SG_ STATE_2 : 55|2@0+ (1,0) [0|3] "" XXX

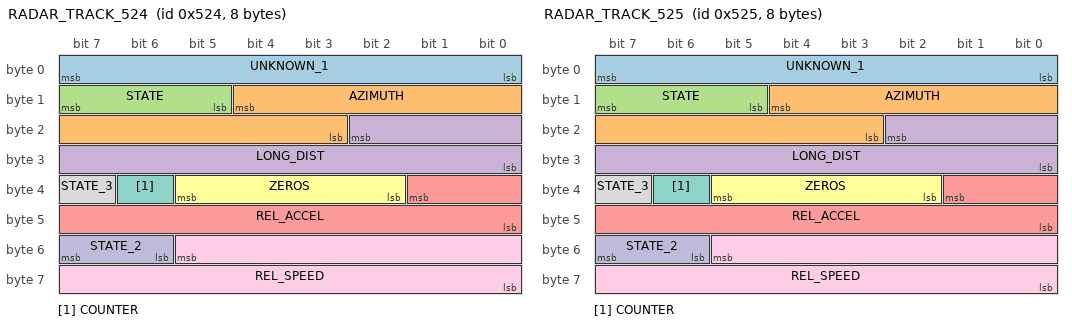
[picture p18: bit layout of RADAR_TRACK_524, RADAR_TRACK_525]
BO_ 1316 RADAR_TRACK_524: 8 RADAR
 SG_ UNKNOWN_1 : 7|8@0- (1,0) [-128|127] "" XXX
 SG_ AZIMUTH : 12|10@0- (0.2,0) [-102.4|102.2] "" XXX
 SG_ STATE : 15|3@0+ (1,0) [0|7] "" XXX
 SG_ LONG_DIST : 18|11@0+ (0.1,0) [0|204.7] "" XXX
 SG_ REL_ACCEL : 33|10@0- (0.02,0) [-10.24|10.22] "" XXX
 SG_ ZEROS : 37|4@0+ (1,0) [0|255] "" XXX
 SG_ COUNTER : 38|1@0+ (1,0) [0|1] "" XXX
 SG_ STATE_3 : 39|1@0+ (1,0) [0|1] "" XXX
 SG_ REL_SPEED : 53|14@0- (0.01,0) [-81.92|81.92] "" XXX
 SG_ STATE_2 : 55|2@0+ (1,0) [0|3] "" XXX

BO_ 1317 RADAR_TRACK_525: 8 RADAR
 SG_ UNKNOWN_1 : 7|8@0- (1,0) [-128|127] "" XXX
 SG_ AZIMUTH : 12|10@0- (0.2,0) [-102.4|102.2] "" XXX
 SG_ STATE : 15|3@0+ (1,0) [0|7] "" XXX
 SG_ LONG_DIST : 18|11@0+ (0.1,0) [0|204.7] "" XXX
 SG_ REL_ACCEL : 33|10@0- (0.02,0) [-10.24|10.22] "" XXX
 SG_ ZEROS : 37|4@0+ (1,0) [0|255] "" XXX
 SG_ COUNTER : 38|1@0+ (1,0) [0|1] "" XXX
 SG_ STATE_3 : 39|1@0+ (1,0) [0|1] "" XXX
 SG_ REL_SPEED : 53|14@0- (0.01,0) [-81.92|81.92] "" XXX
 SG_ STATE_2 : 55|2@0+ (1,0) [0|3] "" XXX

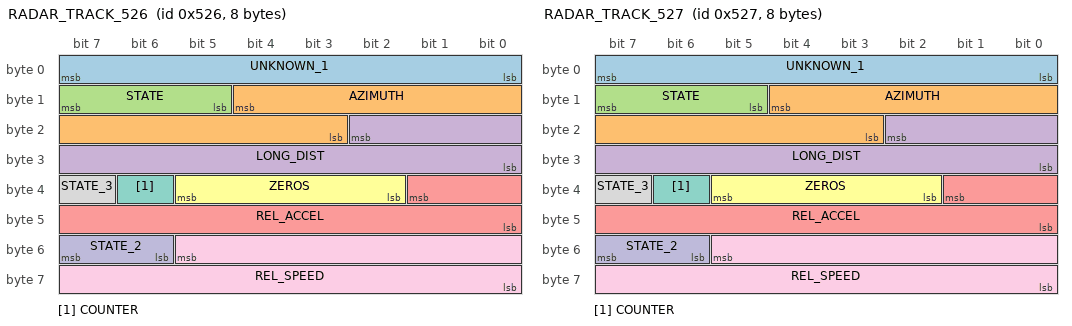
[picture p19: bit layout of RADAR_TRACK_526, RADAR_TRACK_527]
BO_ 1318 RADAR_TRACK_526: 8 RADAR
 SG_ UNKNOWN_1 : 7|8@0- (1,0) [-128|127] "" XXX
 SG_ AZIMUTH : 12|10@0- (0.2,0) [-102.4|102.2] "" XXX
 SG_ STATE : 15|3@0+ (1,0) [0|7] "" XXX
 SG_ LONG_DIST : 18|11@0+ (0.1,0) [0|204.7] "" XXX
 SG_ REL_ACCEL : 33|10@0- (0.02,0) [-10.24|10.22] "" XXX
 SG_ ZEROS : 37|4@0+ (1,0) [0|255] "" XXX
 SG_ COUNTER : 38|1@0+ (1,0) [0|1] "" XXX
 SG_ STATE_3 : 39|1@0+ (1,0) [0|1] "" XXX
 SG_ REL_SPEED : 53|14@0- (0.01,0) [-81.92|81.92] "" XXX
 SG_ STATE_2 : 55|2@0+ (1,0) [0|3] "" XXX

BO_ 1319 RADAR_TRACK_527: 8 RADAR
 SG_ UNKNOWN_1 : 7|8@0- (1,0) [-128|127] "" XXX
 SG_ AZIMUTH : 12|10@0- (0.2,0) [-102.4|102.2] "" XXX
 SG_ STATE : 15|3@0+ (1,0) [0|7] "" XXX
 SG_ LONG_DIST : 18|11@0+ (0.1,0) [0|204.7] "" XXX
 SG_ REL_ACCEL : 33|10@0- (0.02,0) [-10.24|10.22] "" XXX
 SG_ ZEROS : 37|4@0+ (1,0) [0|255] "" XXX
 SG_ COUNTER : 38|1@0+ (1,0) [0|1] "" XXX
 SG_ STATE_3 : 39|1@0+ (1,0) [0|1] "" XXX
 SG_ REL_SPEED : 53|14@0- (0.01,0) [-81.92|81.92] "" XXX
 SG_ STATE_2 : 55|2@0+ (1,0) [0|3] "" XXX

BO_ 1320 RADAR_TRACK_528: 8 RADAR
 SG_ UNKNOWN_1 : 7|8@0- (1,0) [-128|127] "" XXX
 SG_ AZIMUTH : 12|10@0- (0.2,0) [-102.4|102.2] "" XXX
 SG_ STATE : 15|3@0+ (1,0) [0|7] "" XXX
 SG_ LONG_DIST : 18|11@0+ (0.1,0) [0|204.7] "" XXX
 SG_ REL_ACCEL : 33|10@0- (0.02,0) [-10.24|10.22] "" XXX
 SG_ ZEROS : 37|4@0+ (1,0) [0|255] "" XXX
 SG_ COUNTER : 38|1@0+ (1,0) [0|1] "" XXX
 SG_ STATE_3 : 39|1@0+ (1,0) [0|1] "" XXX
 SG_ REL_SPEED : 53|14@0- (0.01,0) [-81.92|81.92] "" XXX
 SG_ STATE_2 : 55|2@0+ (1,0) [0|3] "" XXX

BO_ 1321 RADAR_TRACK_529: 8 RADAR
 SG_ UNKNOWN_1 : 7|8@0- (1,0) [-128|127] "" XXX
 SG_ AZIMUTH : 12|10@0- (0.2,0) [-102.4|102.2] "" XXX
 SG_ STATE : 15|3@0+ (1,0) [0|7] "" XXX
 SG_ LONG_DIST : 18|11@0+ (0.1,0) [0|204.7] "" XXX
 SG_ REL_ACCEL : 33|10@0- (0.02,0) [-10.24|10.22] "" XXX
 SG_ ZEROS : 37|4@0+ (1,0) [0|255] "" XXX
 SG_ COUNTER : 38|1@0+ (1,0) [0|1] "" XXX
 SG_ STATE_3 : 39|1@0+ (1,0) [0|1] "" XXX
 SG_ REL_SPEED : 53|14@0- (0.01,0) [-81.92|81.92] "" XXX
 SG_ STATE_2 : 55|2@0+ (1,0) [0|3] "" XXX

BO_ 1322 RADAR_TRACK_52a: 8 RADAR
 SG_ UNKNOWN_1 : 7|8@0- (1,0) [-128|127] "" XXX
 SG_ AZIMUTH : 12|10@0- (0.2,0) [-102.4|102.2] "" XXX
 SG_ STATE : 15|3@0+ (1,0) [0|7] "" XXX
 SG_ LONG_DIST : 18|11@0+ (0.1,0) [0|204.7] "" XXX
 SG_ REL_ACCEL : 33|10@0- (0.02,0) [-10.24|10.22] "" XXX
 SG_ ZEROS : 37|4@0+ (1,0) [0|255] "" XXX
 SG_ COUNTER : 38|1@0+ (1,0) [0|1] "" XXX
 SG_ STATE_3 : 39|1@0+ (1,0) [0|1] "" XXX
 SG_ REL_SPEED : 53|14@0- (0.01,0) [-81.92|81.92] "" XXX
 SG_ STATE_2 : 55|2@0+ (1,0) [0|3] "" XXX

BO_ 1323 RADAR_TRACK_52b: 8 RADAR
 SG_ UNKNOWN_1 : 7|8@0- (1,0) [-128|127] "" XXX
 SG_ AZIMUTH : 12|10@0- (0.2,0) [-102.4|102.2] "" XXX
 SG_ STATE : 15|3@0+ (1,0) [0|7] "" XXX
 SG_ LONG_DIST : 18|11@0+ (0.1,0) [0|204.7] "" XXX
 SG_ REL_ACCEL : 33|10@0- (0.02,0) [-10.24|10.22] "" XXX
 SG_ ZEROS : 37|4@0+ (1,0) [0|255] "" XXX
 SG_ COUNTER : 38|1@0+ (1,0) [0|1] "" XXX
 SG_ STATE_3 : 39|1@0+ (1,0) [0|1] "" XXX
 SG_ REL_SPEED : 53|14@0- (0.01,0) [-81.92|81.92] "" XXX
 SG_ STATE_2 : 55|2@0+ (1,0) [0|3] "" XXX

BO_ 1324 RADAR_TRACK_52c: 8 RADAR
 SG_ UNKNOWN_1 : 7|8@0- (1,0) [-128|127] "" XXX
 SG_ AZIMUTH : 12|10@0- (0.2,0) [-102.4|102.2] "" XXX
 SG_ STATE : 15|3@0+ (1,0) [0|7] "" XXX
 SG_ LONG_DIST : 18|11@0+ (0.1,0) [0|204.7] "" XXX
 SG_ REL_ACCEL : 33|10@0- (0.02,0) [-10.24|10.22] "" XXX
 SG_ ZEROS : 37|4@0+ (1,0) [0|255] "" XXX
 SG_ COUNTER : 38|1@0+ (1,0) [0|1] "" XXX
 SG_ STATE_3 : 39|1@0+ (1,0) [0|1] "" XXX
 SG_ REL_SPEED : 53|14@0- (0.01,0) [-81.92|81.92] "" XXX
 SG_ STATE_2 : 55|2@0+ (1,0) [0|3] "" XXX

BO_ 1325 RADAR_TRACK_52d: 8 RADAR
 SG_ UNKNOWN_1 : 7|8@0- (1,0) [-128|127] "" XXX
 SG_ AZIMUTH : 12|10@0- (0.2,0) [-102.4|102.2] "" XXX
 SG_ STATE : 15|3@0+ (1,0) [0|7] "" XXX
 SG_ LONG_DIST : 18|11@0+ (0.1,0) [0|204.7] "" XXX
 SG_ REL_ACCEL : 33|10@0- (0.02,0) [-10.24|10.22] "" XXX
 SG_ ZEROS : 37|4@0+ (1,0) [0|255] "" XXX
 SG_ COUNTER : 38|1@0+ (1,0) [0|1] "" XXX
 SG_ STATE_3 : 39|1@0+ (1,0) [0|1] "" XXX
 SG_ REL_SPEED : 53|14@0- (0.01,0) [-81.92|81.92] "" XXX
 SG_ STATE_2 : 55|2@0+ (1,0) [0|3] "" XXX

BO_ 1326 RADAR_TRACK_52e: 8 RADAR
 SG_ UNKNOWN_1 : 7|8@0- (1,0) [-128|127] "" XXX
 SG_ AZIMUTH : 12|10@0- (0.2,0) [-102.4|102.2] "" XXX
 SG_ STATE : 15|3@0+ (1,0) [0|7] "" XXX
 SG_ LONG_DIST : 18|11@0+ (0.1,0) [0|204.7] "" XXX
 SG_ REL_ACCEL : 33|10@0- (0.02,0) [-10.24|10.22] "" XXX
 SG_ ZEROS : 37|4@0+ (1,0) [0|255] "" XXX
 SG_ COUNTER : 38|1@0+ (1,0) [0|1] "" XXX
 SG_ STATE_3 : 39|1@0+ (1,0) [0|1] "" XXX
 SG_ REL_SPEED : 53|14@0- (0.01,0) [-81.92|81.92] "" XXX
 SG_ STATE_2 : 55|2@0+ (1,0) [0|3] "" XXX

BO_ 1327 RADAR_TRACK_52f: 8 RADAR
 SG_ UNKNOWN_1 : 7|8@0- (1,0) [-128|127] "" XXX
 SG_ AZIMUTH : 12|10@0- (0.2,0) [-102.4|102.2] "" XXX
 SG_ STATE : 15|3@0+ (1,0) [0|7] "" XXX
 SG_ LONG_DIST : 18|11@0+ (0.1,0) [0|204.7] "" XXX
 SG_ REL_ACCEL : 33|10@0- (0.02,0) [-10.24|10.22] "" XXX
 SG_ ZEROS : 37|4@0+ (1,0) [0|255] "" XXX
 SG_ COUNTER : 38|1@0+ (1,0) [0|1] "" XXX
 SG_ STATE_3 : 39|1@0+ (1,0) [0|1] "" XXX
 SG_ REL_SPEED : 53|14@0- (0.01,0) [-81.92|81.92] "" XXX
 SG_ STATE_2 : 55|2@0+ (1,0) [0|3] "" XXX

BO_ 1328 RADAR_TRACK_530: 8 RADAR
 SG_ UNKNOWN_1 : 7|8@0- (1,0) [-128|127] "" XXX
 SG_ AZIMUTH : 12|10@0- (0.2,0) [-102.4|102.2] "" XXX
 SG_ STATE : 15|3@0+ (1,0) [0|7] "" XXX
 SG_ LONG_DIST : 18|11@0+ (0.1,0) [0|204.7] "" XXX
 SG_ REL_ACCEL : 33|10@0- (0.02,0) [-10.24|10.22] "" XXX
 SG_ ZEROS : 37|4@0+ (1,0) [0|255] "" XXX
 SG_ COUNTER : 38|1@0+ (1,0) [0|1] "" XXX
 SG_ STATE_3 : 39|1@0+ (1,0) [0|1] "" XXX
 SG_ REL_SPEED : 53|14@0- (0.01,0) [-81.92|81.92] "" XXX
 SG_ STATE_2 : 55|2@0+ (1,0) [0|3] "" XXX

BO_ 1329 RADAR_TRACK_531: 8 RADAR
 SG_ UNKNOWN_1 : 7|8@0- (1,0) [-128|127] "" XXX
 SG_ AZIMUTH : 12|10@0- (0.2,0) [-102.4|102.2] "" XXX
 SG_ STATE : 15|3@0+ (1,0) [0|7] "" XXX
 SG_ LONG_DIST : 18|11@0+ (0.1,0) [0|204.7] "" XXX
 SG_ REL_ACCEL : 33|10@0- (0.02,0) [-10.24|10.22] "" XXX
 SG_ ZEROS : 37|4@0+ (1,0) [0|255] "" XXX
 SG_ COUNTER : 38|1@0+ (1,0) [0|1] "" XXX
 SG_ STATE_3 : 39|1@0+ (1,0) [0|1] "" XXX
 SG_ REL_SPEED : 53|14@0- (0.01,0) [-81.92|81.92] "" XXX
 SG_ STATE_2 : 55|2@0+ (1,0) [0|3] "" XXX

BO_ 1330 RADAR_TRACK_532: 8 RADAR
 SG_ UNKNOWN_1 : 7|8@0- (1,0) [-128|127] "" XXX
 SG_ AZIMUTH : 12|10@0- (0.2,0) [-102.4|102.2] "" XXX
 SG_ STATE : 15|3@0+ (1,0) [0|7] "" XXX
 SG_ LONG_DIST : 18|11@0+ (0.1,0) [0|204.7] "" XXX
 SG_ REL_ACCEL : 33|10@0- (0.02,0) [-10.24|10.22] "" XXX
 SG_ ZEROS : 37|4@0+ (1,0) [0|255] "" XXX
 SG_ COUNTER : 38|1@0+ (1,0) [0|1] "" XXX
 SG_ STATE_3 : 39|1@0+ (1,0) [0|1] "" XXX
 SG_ REL_SPEED : 53|14@0- (0.01,0) [-81.92|81.92] "" XXX
 SG_ STATE_2 : 55|2@0+ (1,0) [0|3] "" XXX

BO_ 1331 RADAR_TRACK_533: 8 RADAR
 SG_ UNKNOWN_1 : 7|8@0- (1,0) [-128|127] "" XXX
 SG_ AZIMUTH : 12|10@0- (0.2,0) [-102.4|102.2] "" XXX
 SG_ STATE : 15|3@0+ (1,0) [0|7] "" XXX
 SG_ LONG_DIST : 18|11@0+ (0.1,0) [0|204.7] "" XXX
 SG_ REL_ACCEL : 33|10@0- (0.02,0) [-10.24|10.22] "" XXX
 SG_ ZEROS : 37|4@0+ (1,0) [0|255] "" XXX
 SG_ COUNTER : 38|1@0+ (1,0) [0|1] "" XXX
 SG_ STATE_3 : 39|1@0+ (1,0) [0|1] "" XXX
 SG_ REL_SPEED : 53|14@0- (0.01,0) [-81.92|81.92] "" XXX
 SG_ STATE_2 : 55|2@0+ (1,0) [0|3] "" XXX

BO_ 1332 RADAR_TRACK_534: 8 RADAR
 SG_ UNKNOWN_1 : 7|8@0- (1,0) [-128|127] "" XXX
 SG_ AZIMUTH : 12|10@0- (0.2,0) [-102.4|102.2] "" XXX
 SG_ STATE : 15|3@0+ (1,0) [0|7] "" XXX
 SG_ LONG_DIST : 18|11@0+ (0.1,0) [0|204.7] "" XXX
 SG_ REL_ACCEL : 33|10@0- (0.02,0) [-10.24|10.22] "" XXX
 SG_ ZEROS : 37|4@0+ (1,0) [0|255] "" XXX
 SG_ COUNTER : 38|1@0+ (1,0) [0|1] "" XXX
 SG_ STATE_3 : 39|1@0+ (1,0) [0|1] "" XXX
 SG_ REL_SPEED : 53|14@0- (0.01,0) [-81.92|81.92] "" XXX
 SG_ STATE_2 : 55|2@0+ (1,0) [0|3] "" XXX

BO_ 1333 RADAR_TRACK_535: 8 RADAR
 SG_ UNKNOWN_1 : 7|8@0- (1,0) [-128|127] "" XXX
 SG_ AZIMUTH : 12|10@0- (0.2,0) [-102.4|102.2] "" XXX
 SG_ STATE : 15|3@0+ (1,0) [0|7] "" XXX
 SG_ LONG_DIST : 18|11@0+ (0.1,0) [0|204.7] "" XXX
 SG_ REL_ACCEL : 33|10@0- (0.02,0) [-10.24|10.22] "" XXX
 SG_ ZEROS : 37|4@0+ (1,0) [0|255] "" XXX
 SG_ COUNTER : 38|1@0+ (1,0) [0|1] "" XXX
 SG_ STATE_3 : 39|1@0+ (1,0) [0|1] "" XXX
 SG_ REL_SPEED : 53|14@0- (0.01,0) [-81.92|81.92] "" XXX
 SG_ STATE_2 : 55|2@0+ (1,0) [0|3] "" XXX

BO_ 1334 RADAR_TRACK_536: 8 RADAR
 SG_ UNKNOWN_1 : 7|8@0- (1,0) [-128|127] "" XXX
 SG_ AZIMUTH : 12|10@0- (0.2,0) [-102.4|102.2] "" XXX
 SG_ STATE : 15|3@0+ (1,0) [0|7] "" XXX
 SG_ LONG_DIST : 18|11@0+ (0.1,0) [0|204.7] "" XXX
 SG_ REL_ACCEL : 33|10@0- (0.02,0) [-10.24|10.22] "" XXX
 SG_ ZEROS : 37|4@0+ (1,0) [0|255] "" XXX
 SG_ COUNTER : 38|1@0+ (1,0) [0|1] "" XXX
 SG_ STATE_3 : 39|1@0+ (1,0) [0|1] "" XXX
 SG_ REL_SPEED : 53|14@0- (0.01,0) [-81.92|81.92] "" XXX
 SG_ STATE_2 : 55|2@0+ (1,0) [0|3] "" XXX

BO_ 1335 RADAR_TRACK_537: 8 RADAR
 SG_ UNKNOWN_1 : 7|8@0- (1,0) [-128|127] "" XXX
 SG_ AZIMUTH : 12|10@0- (0.2,0) [-102.4|102.2] "" XXX
 SG_ STATE : 15|3@0+ (1,0) [0|7] "" XXX
 SG_ LONG_DIST : 18|11@0+ (0.1,0) [0|204.7] "" XXX
 SG_ REL_ACCEL : 33|10@0- (0.02,0) [-10.24|10.22] "" XXX
 SG_ ZEROS : 37|4@0+ (1,0) [0|255] "" XXX
 SG_ COUNTER : 38|1@0+ (1,0) [0|1] "" XXX
 SG_ STATE_3 : 39|1@0+ (1,0) [0|1] "" XXX
 SG_ REL_SPEED : 53|14@0- (0.01,0) [-81.92|81.92] "" XXX
 SG_ STATE_2 : 55|2@0+ (1,0) [0|3] "" XXX

BO_ 1336 RADAR_TRACK_538: 8 RADAR
 SG_ UNKNOWN_1 : 7|8@0- (1,0) [-128|127] "" XXX
 SG_ AZIMUTH : 12|10@0- (0.2,0) [-102.4|102.2] "" XXX
 SG_ STATE : 15|3@0+ (1,0) [0|7] "" XXX
 SG_ LONG_DIST : 18|11@0+ (0.1,0) [0|204.7] "" XXX
 SG_ REL_ACCEL : 33|10@0- (0.02,0) [-10.24|10.22] "" XXX
 SG_ ZEROS : 37|4@0+ (1,0) [0|255] "" XXX
 SG_ COUNTER : 38|1@0+ (1,0) [0|1] "" XXX
 SG_ STATE_3 : 39|1@0+ (1,0) [0|1] "" XXX
 SG_ REL_SPEED : 53|14@0- (0.01,0) [-81.92|81.92] "" XXX
 SG_ STATE_2 : 55|2@0+ (1,0) [0|3] "" XXX

BO_ 1337 RADAR_TRACK_539: 8 RADAR
 SG_ UNKNOWN_1 : 7|8@0- (1,0) [-128|127] "" XXX
 SG_ AZIMUTH : 12|10@0- (0.2,0) [-102.4|102.2] "" XXX
 SG_ STATE : 15|3@0+ (1,0) [0|7] "" XXX
 SG_ LONG_DIST : 18|11@0+ (0.1,0) [0|204.7] "" XXX
 SG_ REL_ACCEL : 33|10@0- (0.02,0) [-10.24|10.22] "" XXX
 SG_ ZEROS : 37|4@0+ (1,0) [0|255] "" XXX
 SG_ COUNTER : 38|1@0+ (1,0) [0|1] "" XXX
 SG_ STATE_3 : 39|1@0+ (1,0) [0|1] "" XXX
 SG_ REL_SPEED : 53|14@0- (0.01,0) [-81.92|81.92] "" XXX
 SG_ STATE_2 : 55|2@0+ (1,0) [0|3] "" XXX

BO_ 1338 RADAR_TRACK_53a: 8 RADAR
 SG_ UNKNOWN_1 : 7|8@0- (1,0) [-128|127] "" XXX
 SG_ AZIMUTH : 12|10@0- (0.2,0) [-102.4|102.2] "" XXX
 SG_ STATE : 15|3@0+ (1,0) [0|7] "" XXX
 SG_ LONG_DIST : 18|11@0+ (0.1,0) [0|204.7] "" XXX
 SG_ REL_ACCEL : 33|10@0- (0.02,0) [-10.24|10.22] "" XXX
 SG_ ZEROS : 37|4@0+ (1,0) [0|255] "" XXX
 SG_ COUNTER : 38|1@0+ (1,0) [0|1] "" XXX
 SG_ STATE_3 : 39|1@0+ (1,0) [0|1] "" XXX
 SG_ REL_SPEED : 53|14@0- (0.01,0) [-81.92|81.92] "" XXX
 SG_ STATE_2 : 55|2@0+ (1,0) [0|3] "" XXX

BO_ 1339 RADAR_TRACK_53b: 8 RADAR
 SG_ UNKNOWN_1 : 7|8@0- (1,0) [-128|127] "" XXX
 SG_ AZIMUTH : 12|10@0- (0.2,0) [-102.4|102.2] "" XXX
 SG_ STATE : 15|3@0+ (1,0) [0|7] "" XXX
 SG_ LONG_DIST : 18|11@0+ (0.1,0) [0|204.7] "" XXX
 SG_ REL_ACCEL : 33|10@0- (0.02,0) [-10.24|10.22] "" XXX
 SG_ ZEROS : 37|4@0+ (1,0) [0|255] "" XXX
 SG_ COUNTER : 38|1@0+ (1,0) [0|1] "" XXX
 SG_ STATE_3 : 39|1@0+ (1,0) [0|1] "" XXX
 SG_ REL_SPEED : 53|14@0- (0.01,0) [-81.92|81.92] "" XXX
 SG_ STATE_2 : 55|2@0+ (1,0) [0|3] "" XXX

BO_ 1340 RADAR_TRACK_53c: 8 RADAR
 SG_ UNKNOWN_1 : 7|8@0- (1,0) [-128|127] "" XXX
 SG_ AZIMUTH : 12|10@0- (0.2,0) [-102.4|102.2] "" XXX
 SG_ STATE : 15|3@0+ (1,0) [0|7] "" XXX
 SG_ LONG_DIST : 18|11@0+ (0.1,0) [0|204.7] "" XXX
 SG_ REL_ACCEL : 33|10@0- (0.02,0) [-10.24|10.22] "" XXX
 SG_ ZEROS : 37|4@0+ (1,0) [0|255] "" XXX
 SG_ COUNTER : 38|1@0+ (1,0) [0|1] "" XXX
 SG_ STATE_3 : 39|1@0+ (1,0) [0|1] "" XXX
 SG_ REL_SPEED : 53|14@0- (0.01,0) [-81.92|81.92] "" XXX
 SG_ STATE_2 : 55|2@0+ (1,0) [0|3] "" XXX

BO_ 1341 RADAR_TRACK_53d: 8 RADAR
 SG_ UNKNOWN_1 : 7|8@0- (1,0) [-128|127] "" XXX
 SG_ AZIMUTH : 12|10@0- (0.2,0) [-102.4|102.2] "" XXX
 SG_ STATE : 15|3@0+ (1,0) [0|7] "" XXX
 SG_ LONG_DIST : 18|11@0+ (0.1,0) [0|204.7] "" XXX
 SG_ REL_ACCEL : 33|10@0- (0.02,0) [-10.24|10.22] "" XXX
 SG_ ZEROS : 37|4@0+ (1,0) [0|255] "" XXX
 SG_ COUNTER : 38|1@0+ (1,0) [0|1] "" XXX
 SG_ STATE_3 : 39|1@0+ (1,0) [0|1] "" XXX
 SG_ REL_SPEED : 53|14@0- (0.01,0) [-81.92|81.92] "" XXX
 SG_ STATE_2 : 55|2@0+ (1,0) [0|3] "" XXX

BO_ 1342 RADAR_TRACK_53e: 8 RADAR
 SG_ UNKNOWN_1 : 7|8@0- (1,0) [-128|127] "" XXX
 SG_ AZIMUTH : 12|10@0- (0.2,0) [-102.4|102.2] "" XXX
 SG_ STATE : 15|3@0+ (1,0) [0|7] "" XXX
 SG_ LONG_DIST : 18|11@0+ (0.1,0) [0|204.7] "" XXX
 SG_ REL_ACCEL : 33|10@0- (0.02,0) [-10.24|10.22] "" XXX
 SG_ ZEROS : 37|4@0+ (1,0) [0|255] "" XXX
 SG_ COUNTER : 38|1@0+ (1,0) [0|1] "" XXX
 SG_ STATE_3 : 39|1@0+ (1,0) [0|1] "" XXX
 SG_ REL_SPEED : 53|14@0- (0.01,0) [-81.92|81.92] "" XXX
 SG_ STATE_2 : 55|2@0+ (1,0) [0|3] "" XXX

BO_ 1343 RADAR_TRACK_53f: 8 RADAR
 SG_ UNKNOWN_1 : 7|8@0- (1,0) [-128|127] "" XXX
 SG_ AZIMUTH : 12|10@0- (0.2,0) [-102.4|102.2] "" XXX
 SG_ STATE : 15|3@0+ (1,0) [0|7] "" XXX
 SG_ LONG_DIST : 18|11@0+ (0.1,0) [0|204.7] "" XXX
 SG_ REL_ACCEL : 33|10@0- (0.02,0) [-10.24|10.22] "" XXX
 SG_ ZEROS : 37|4@0+ (1,0) [0|255] "" XXX
 SG_ COUNTER : 38|1@0+ (1,0) [0|1] "" XXX
 SG_ STATE_3 : 39|1@0+ (1,0) [0|1] "" XXX
 SG_ REL_SPEED : 53|14@0- (0.01,0) [-81.92|81.92] "" XXX
 SG_ STATE_2 : 55|2@0+ (1,0) [0|3] "" XXX
